# STM32L152xDx register map
File version: 1.0
Registers are 32-bit, read-write, reset 0x0 unless marked. A register's access mark holds for its fields unless they carry their own. Offsets are from the block's base; [hi:lo] are bit positions; {n}, {i} and the like mark numbered series.

## OB — Option Bytes Registers
Base 0x1FF80000
0x00 RDP — Read protection register
0x04 USER
0x08 WRP01 — write protection register 0 1
0x0C WRP23 — write protection register 2 3
0x10 WRP45 — write protection register 4 5
0x14 WRP67 — write protection register 6 7
0x18 WRP89 — write protection register 8 9
0x1C WRP1011 — write protection register 10 11
0x80 WRP1213 — write protection register 12 13
0x84 WRP1415 — write protection register 14 15

## TIM6 — TIM
Base 0x40001000
Same registers: TIM7 0x40001400
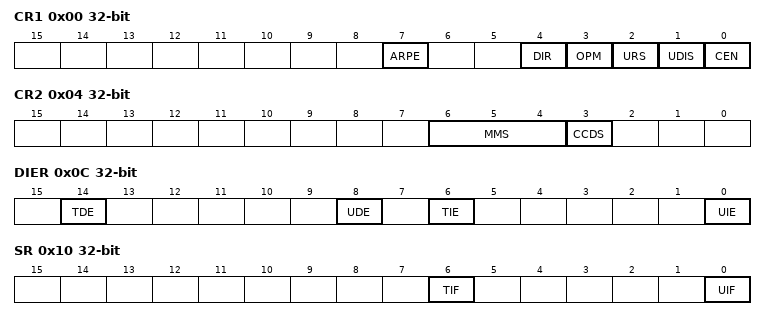
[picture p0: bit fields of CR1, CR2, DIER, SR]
0x00 CR1 — TIM control register 1
  [7] ARPE — Auto-reload preload enable
  [4] DIR — Direction
    0=UP (Timer counter counts up); 1=DOWN (Timer counter counts down)
  [3] OPM — One pulse mode
    1=SINGLE (Counter stops counting at the next update event); 0=REPETITIVE (Counter is not stopped at update event)
  [2] URS — Update request source
    0=REGULAR (Counter overflow/underflow, Setting the UG bit or Update generation through the slave mode controller generates an update request); 1=COUNTER (Only counter overflow/underflow generates an update request)
  [1] UDIS — Update disable
  [0] CEN — Counter enable
0x04 CR2 — TIM control register 2
  [6:4] MMS — MMS[2:0] bits (Master Mode Selection)
    0=RESET (UG bit from the TIMx_EGR register is used as trigger output); 1=ENABLE (Counter Enable signal (CNT_EN) is used as trigger output); 2=UPDATE (Update event is used as trigger output); 3=CC1IF (CC1 capture or a compare match is used as trigger output); {v}=OC{v-3}REF (OC{v-3}REF signal is used as trigger output) (v=4..7)
  [3] CCDS — Capture/Compare DMA Selection
    0=CC (CCx DMA request sent when CCx event occurs); 1=UPDATE (CCx DMA requests sent when update event occurs)
0x08 SMCR — TIM slave Mode Control register
  [3] OCCS — OCREF clear selection
    0=OCREF_CLR (OCREF_CLR_INT is connected to the OCREF_CLR input); 1=ETR (OCREF_CLR_INT is connected to ETRF)
0x0C DIER — TIM DMA/interrupt enable register
  [14] TDE — Trigger DMA request enable
  [8] UDE — Update DMA request enable
  [6] TIE — Trigger interrupt enable
  [0] UIE — Update interrupt enable
0x10 SR — TIM status register
  [6] TIF — Trigger interrupt Flag
  [0] UIF — Update interrupt Flag
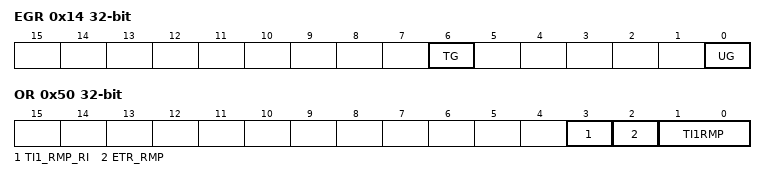
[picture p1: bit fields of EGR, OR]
0x14 EGR — TIM event generation register
  [6] TG — Trigger Generation
  [0] UG — Update Generation
0x24 CNT — TIM counter register
  [15:0] CNT — Counter Value
0x28 PSC — TIM prescaler register
  [15:0] PSC — Prescaler Value
0x2C ARR — TIM auto-reload register
  [15:0] ARR — actual auto-reload Value
0x4C DMAR — TIM DMA address for full transfer
  [15:0] DMAB — DMA register for burst accesses
0x50 OR — TIM option register
  [3] TI1_RMP_RI — TI1_RMP_RI bit (TIM10/11 Input 1 remap for Routing interface)
  [2] ETR_RMP — ETR_RMP bit (TIM10/11 ETR remap)
  [1:0] TI1RMP — TI1_RMP[1:0] bits (TIM Input 1 remap)

## LCD
Base 0x40002400
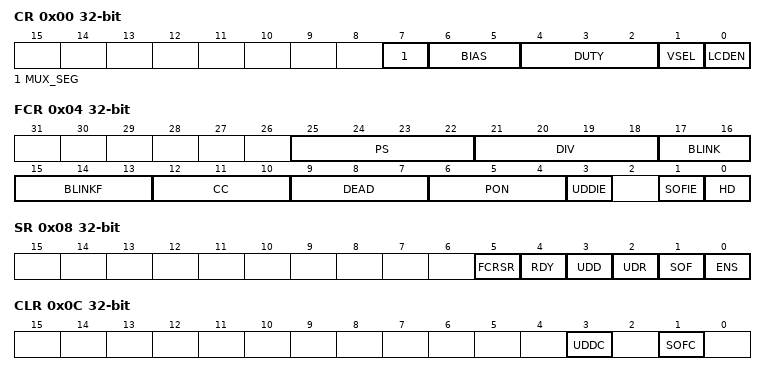
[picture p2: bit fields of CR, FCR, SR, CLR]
0x00 CR — LCD control register
  [7] MUX_SEG — Mux Segment Enable Bit
  [6:5] BIAS — BIAS[1:0] bits (Bias selector)
  [4:2] DUTY — DUTY[2:0] bits (Duty selector)
  [1] VSEL — Voltage source selector Bit
  [0] LCDEN — LCD Enable Bit
0x04 FCR — LCD frame control register
  [25:22] PS — PS[3:0] bits (Prescaler)
  [21:18] DIV — DIV[3:0] bits (Divider)
  [17:16] BLINK — BLINK[1:0] bits (Blink Enable)
  [15:13] BLINKF — BLINKF[2:0] bits (Blink Frequency)
  [12:10] CC — CC[2:0] bits (Contrast Control)
  [9:7] DEAD — DEAD[2:0] bits (DEAD Time)
  [6:4] PON — PON[2:0] bits (Pulse ON Duration)
  [3] UDDIE — Update Display Done Interrupt Enable Bit
  [1] SOFIE — Start of Frame Interrupt Enable Bit
  [0] HD — High Drive Enable Bit
0x08 SR — LCD status register
  [5] FCRSR — LCD FCR Register Synchronization Flag Bit
  [4] RDY — Ready Flag Bit
  [3] UDD — Update Display Done Flag Bit
  [2] UDR — Update Display Request Bit
  [1] SOF — Start Of Frame Flag Bit
  [0] ENS — LCD Enabled Bit
0x0C CLR — LCD clear register
  [3] UDDC — Update Display Done Flag Clear Bit
  [1] SOFC — Start Of Frame Flag Clear Bit
{0x14+4i} RAM{i} (i=0..15) — LCD display memory
  [31:0] SEGMENT_DATA — Segment Data Bits
